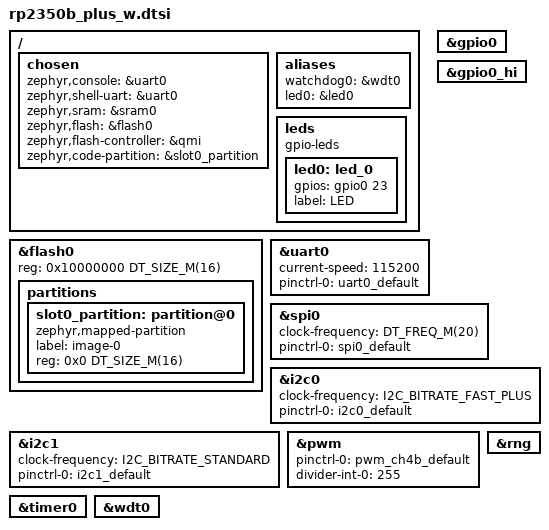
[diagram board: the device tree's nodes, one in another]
/*
 * SPDX-FileCopyrightText: Copyright (c) 2026 MASSDRIVER EI (massdriver.space)
 * SPDX-FileCopyrightText: Copyright (c) 2026 Matheus de Alencar
 *
 * SPDX-License-Identifier: Apache-2.0
 */

#include <freq.h>

#include <zephyr/dt-bindings/i2c/i2c.h>
#include <zephyr/dt-bindings/pwm/pwm.h>
#include <zephyr/dt-bindings/input/input-event-codes.h>

#include "rp2350b_plus_w-pinctrl.dtsi"

/ {
	chosen {
		zephyr,console = &uart0;
		zephyr,shell-uart = &uart0;
		zephyr,sram = &sram0;
		zephyr,flash = &flash0;
		zephyr,flash-controller = &qmi;
		zephyr,code-partition = &slot0_partition;
	};

	aliases {
		watchdog0 = &wdt0;
	};

	leds {
		compatible = "gpio-leds";

		led0: led_0 {
			gpios = <&gpio0 23 GPIO_ACTIVE_HIGH>;
			label = "LED";
		};
	};

	aliases {
		led0 = &led0;
	};
};

&flash0 {
	reg = <0x10000000 DT_SIZE_M(16)>;
	ranges = <0x0 0x10000000 DT_SIZE_M(16)>;
	status = "okay";

	partitions {
		ranges;
		#address-cells = <0x1>;
		#size-cells = <0x1>;

		slot0_partition: partition@0 {
			compatible = "zephyr,mapped-partition";
			label = "image-0";
			reg = <0x0 DT_SIZE_M(16)>;
		};
	};
};

&uart0 {
	current-speed = <115200>;
	status = "okay";
	pinctrl-0 = <&uart0_default>;
	pinctrl-names = "default";
};

gpio0_lo: &gpio0 {
	status = "okay";
};

gpio1: &gpio0_hi {
	status = "okay";
};

&spi0 {
	clock-frequency = <DT_FREQ_M(20)>;
	pinctrl-0 = <&spi0_default>;
	pinctrl-names = "default";
	status = "okay";
};

&i2c0 {
	clock-frequency = <I2C_BITRATE_FAST_PLUS>;
	pinctrl-0 = <&i2c0_default>;
	pinctrl-names = "default";
	status = "okay";
};

&i2c1 {
	clock-frequency = <I2C_BITRATE_STANDARD>;
	pinctrl-0 = <&i2c1_default>;
	pinctrl-names = "default";
	status = "okay";
};

&pwm {
	pinctrl-0 = <&pwm_ch4b_default>;
	pinctrl-names = "default";
	divider-int-0 = <255>;
};

&timer0 {
	status = "okay";
};

&wdt0 {
	status = "okay";
};

&rng {
	status = "okay";
};
